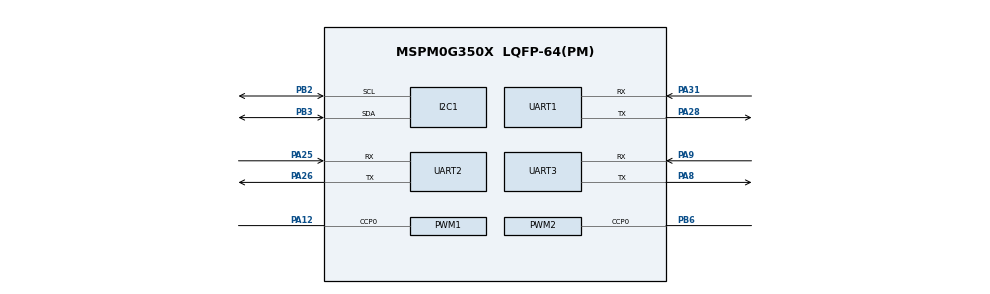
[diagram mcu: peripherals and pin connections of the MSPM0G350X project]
/**
 * @cliArgs --device "MSPM0G350X" --part "Default" --package "LQFP-64(PM)" --product "mspm0_sdk@2.10.00.04"
 * @versions {"tool":"1.26.2+4477"}
 */

/**
 * Import the modules used in this configuration.
 */
const GPIO    = scripting.addModule("/ti/driverlib/GPIO", {}, false);
const GPIO1   = GPIO.addInstance();
const GPIO2   = GPIO.addInstance();
const GPIO3   = GPIO.addInstance();
const GPIO4   = GPIO.addInstance();
const I2C     = scripting.addModule("/ti/driverlib/I2C", {}, false);
const I2C1    = I2C.addInstance();
const PWM     = scripting.addModule("/ti/driverlib/PWM", {}, false);
const PWM1    = PWM.addInstance();
const PWM2    = PWM.addInstance();
const SYSCTL  = scripting.addModule("/ti/driverlib/SYSCTL");
const SYSTICK = scripting.addModule("/ti/driverlib/SYSTICK");
const UART    = scripting.addModule("/ti/driverlib/UART", {}, false);
const UART1   = UART.addInstance();
const UART2   = UART.addInstance();
const UART3   = UART.addInstance();
const UART4   = UART.addInstance();

/**
 * Write custom configuration values to the imported modules.
 */
const divider6       = system.clockTree["PLL_CLK2X_DIV"];
divider6.divideValue = 4;

const divider7       = system.clockTree["PLL_PDIV"];
divider7.divideValue = 2;

const divider9       = system.clockTree["UDIV"];
divider9.divideValue = 2;

const multiplier2         = system.clockTree["PLL_QDIV"];
multiplier2.multiplyValue = 10;

const mux8       = system.clockTree["HSCLKMUX"];
mux8.inputSelect = "HSCLKMUX_SYSPLL2X";

GPIO1.$name                         = "MOTOR_DIR";
GPIO1.port                          = "PORTA";
GPIO1.associatedPins.create(4);
GPIO1.associatedPins[0].$name       = "MOTOR1_DIR";
GPIO1.associatedPins[0].assignedPin = "16";
GPIO1.associatedPins[1].$name       = "MOTOR2_DIR";
GPIO1.associatedPins[1].assignedPin = "17";
GPIO1.associatedPins[2].$name       = "MOTOR1_ENABLE";
GPIO1.associatedPins[2].assignedPin = "18";
GPIO1.associatedPins[3].$name       = "MOTOR2_ENABLE";
GPIO1.associatedPins[3].assignedPin = "15";

const Board = scripting.addModule("/ti/driverlib/Board", {}, false);

GPIO2.$name                          = "LINE_SENSOR";
GPIO2.port                           = "PORTB";
GPIO2.associatedPins.create(12);
GPIO2.associatedPins[0].$name        = "LINE0";
GPIO2.associatedPins[0].direction    = "INPUT";
GPIO2.associatedPins[0].assignedPin  = "0";
GPIO2.associatedPins[1].$name        = "LINE1";
GPIO2.associatedPins[1].direction    = "INPUT";
GPIO2.associatedPins[1].assignedPin  = "1";
GPIO2.associatedPins[2].$name        = "LINE2";
GPIO2.associatedPins[2].direction    = "INPUT";
GPIO2.associatedPins[2].assignedPin  = "4";
GPIO2.associatedPins[3].$name        = "LINE3";
GPIO2.associatedPins[3].direction    = "INPUT";
GPIO2.associatedPins[3].assignedPin  = "5";
GPIO2.associatedPins[4].$name        = "LINE4";
GPIO2.associatedPins[4].direction    = "INPUT";
GPIO2.associatedPins[4].assignedPin  = "7";
GPIO2.associatedPins[5].$name        = "LINE5";
GPIO2.associatedPins[5].direction    = "INPUT";
GPIO2.associatedPins[5].assignedPin  = "8";
GPIO2.associatedPins[6].$name        = "LINE6";
GPIO2.associatedPins[6].direction    = "INPUT";
GPIO2.associatedPins[6].assignedPin  = "9";
GPIO2.associatedPins[7].$name        = "LINE7";
GPIO2.associatedPins[7].direction    = "INPUT";
GPIO2.associatedPins[7].assignedPin  = "10";
GPIO2.associatedPins[8].$name        = "LINE8";
GPIO2.associatedPins[8].direction    = "INPUT";
GPIO2.associatedPins[8].assignedPin  = "11";
GPIO2.associatedPins[9].$name        = "LINE9";
GPIO2.associatedPins[9].direction    = "INPUT";
GPIO2.associatedPins[9].assignedPin  = "12";
GPIO2.associatedPins[10].$name       = "LINE10";
GPIO2.associatedPins[10].direction   = "INPUT";
GPIO2.associatedPins[10].assignedPin = "13";
GPIO2.associatedPins[11].$name       = "LINE11";
GPIO2.associatedPins[11].direction   = "INPUT";
GPIO2.associatedPins[11].assignedPin = "14";

GPIO3.$name                              = "BUTTONS";
GPIO3.port                               = "PORTA";
GPIO3.associatedPins.create(3);
GPIO3.associatedPins[0].$name            = "MODE";
GPIO3.associatedPins[0].direction        = "INPUT";
GPIO3.associatedPins[0].internalResistor = "PULL_UP";
GPIO3.associatedPins[0].assignedPin      = "14";
GPIO3.associatedPins[1].$name            = "UP";
GPIO3.associatedPins[1].direction        = "INPUT";
GPIO3.associatedPins[1].internalResistor = "PULL_UP";
GPIO3.associatedPins[1].assignedPin      = "24";
GPIO3.associatedPins[2].$name            = "DOWN";
GPIO3.associatedPins[2].direction        = "INPUT";
GPIO3.associatedPins[2].internalResistor = "PULL_UP";
GPIO3.associatedPins[2].assignedPin      = "29";

GPIO4.$name                              = "EXTRA_BUTTONS";
GPIO4.port                               = "PORTA";
GPIO4.associatedPins.create(5);
GPIO4.associatedPins[0].$name            = "KEY1";
GPIO4.associatedPins[0].direction        = "INPUT";
GPIO4.associatedPins[0].internalResistor = "PULL_UP";
GPIO4.associatedPins[0].assignedPin      = "30";
GPIO4.associatedPins[1].$name            = "KEY2";
GPIO4.associatedPins[1].direction        = "INPUT";
GPIO4.associatedPins[1].internalResistor = "PULL_UP";
GPIO4.associatedPins[1].assignedPin      = "7";
GPIO4.associatedPins[2].$name            = "KEY3";
GPIO4.associatedPins[2].direction        = "INPUT";
GPIO4.associatedPins[2].internalResistor = "PULL_UP";
GPIO4.associatedPins[2].assignedPin      = "10";
GPIO4.associatedPins[3].$name            = "KEY4";
GPIO4.associatedPins[3].direction        = "INPUT";
GPIO4.associatedPins[3].internalResistor = "PULL_UP";
GPIO4.associatedPins[3].assignedPin      = "11";
GPIO4.associatedPins[4].$name            = "KEY5";
GPIO4.associatedPins[4].direction        = "INPUT";
GPIO4.associatedPins[4].internalResistor = "PULL_UP";
GPIO4.associatedPins[4].assignedPin      = "13";

I2C1.$name                             = "OLED";
I2C1.basicEnableController             = true;
I2C1.advDigitalGlitchFilter            = "CLOCKS_1";
I2C1.basicControllerStandardBusSpeed   = "Fast";
I2C1.peripheral.$assign                = "I2C1";
I2C1.peripheral.sdaPin.$assign         = "PB3";
I2C1.peripheral.sclPin.$assign         = "PB2";
I2C1.sdaPinConfig.hideOutputInversion  = scripting.forceWrite(false);
I2C1.sdaPinConfig.onlyInternalResistor = scripting.forceWrite(false);
I2C1.sdaPinConfig.passedPeripheralType = scripting.forceWrite("Digital");
I2C1.sdaPinConfig.$name                = "OLED_SDA";
I2C1.sdaPinConfig.enableConfig         = true;
I2C1.sdaPinConfig.internalResistor     = "PULL_UP";
I2C1.sclPinConfig.hideOutputInversion  = scripting.forceWrite(false);
I2C1.sclPinConfig.onlyInternalResistor = scripting.forceWrite(false);
I2C1.sclPinConfig.passedPeripheralType = scripting.forceWrite("Digital");
I2C1.sclPinConfig.$name                = "OLED_SCL";
I2C1.sclPinConfig.enableConfig         = true;
I2C1.sclPinConfig.internalResistor     = "PULL_UP";

PWM1.$name                              = "PITCH_PWM";
PWM1.timerCount                         = 3500;
PWM1.clockDivider                       = 8;
PWM1.ccIndex                            = [0];
PWM1.PWM_CHANNEL_0.$name                = "MOTOR1_STEP";
PWM1.PWM_CHANNEL_0.dutyCycle            = 1;
PWM1.PWM_CHANNEL_0.ccValue              = 3475;
PWM1.ccp0PinConfig.direction            = scripting.forceWrite("OUTPUT");
PWM1.ccp0PinConfig.hideOutputInversion  = scripting.forceWrite(false);
PWM1.ccp0PinConfig.onlyInternalResistor = scripting.forceWrite(false);
PWM1.ccp0PinConfig.passedPeripheralType = scripting.forceWrite("Digital");
PWM1.ccp0PinConfig.$name                = "ti_driverlib_gpio_GPIOPinGeneric0";
PWM1.peripheral.$assign                 = "TIMG0";
PWM1.peripheral.ccp0Pin.$assign         = "PA12";

PWM2.$name                              = "YAW_PWM";
PWM2.timerCount                         = 3500;
PWM2.clockDivider                       = 8;
PWM2.clockPrescale                      = 2;
PWM2.ccIndex                            = [0];
PWM2.PWM_CHANNEL_0.$name                = "MOTOR2_STEP";
PWM2.PWM_CHANNEL_0.dutyCycle            = 1;
PWM2.PWM_CHANNEL_0.ccValue              = 3475;
PWM2.ccp0PinConfig.direction            = scripting.forceWrite("OUTPUT");
PWM2.ccp0PinConfig.hideOutputInversion  = scripting.forceWrite(false);
PWM2.ccp0PinConfig.onlyInternalResistor = scripting.forceWrite(false);
PWM2.ccp0PinConfig.passedPeripheralType = scripting.forceWrite("Digital");
PWM2.ccp0PinConfig.$name                = "ti_driverlib_gpio_GPIOPinGeneric2";
PWM2.peripheral.$assign                 = "TIMG6";
PWM2.peripheral.ccp0Pin.$assign         = "PB6";

SYSCTL.MCLKSource            = "HSCLK";
SYSCTL.SYSPLL_CLK2XEn        = true;
SYSCTL.SYSPLL_CLK2XDiv       = 1;
SYSCTL.HSCLKSource           = "SYSPLLCLK2X";
SYSCTL.validateClkStatus     = true;
SYSCTL.SYSPLL_Qdiv           = 5;
SYSCTL.forceDefaultClkConfig = true;
SYSCTL.clockTreeEn           = true;

SYSTICK.systickEnable = true;
SYSTICK.periodEnable  = true;
SYSTICK.period        = 80000;

UART1.$name                            = "TRACKING_UART";
UART1.enabledInterrupts                = ["FRAMING_ERROR","NOISE_ERROR","OVERRUN_ERROR","PARITY_ERROR","RX"];
UART1.targetBaudRate                   = 230400;
UART1.peripheral.$assign               = "UART0";
UART1.peripheral.rxPin.$assign         = "PA31";
UART1.peripheral.txPin.$assign         = "PA28";
UART1.txPinConfig.direction            = scripting.forceWrite("OUTPUT");
UART1.txPinConfig.hideOutputInversion  = scripting.forceWrite(false);
UART1.txPinConfig.onlyInternalResistor = scripting.forceWrite(false);
UART1.txPinConfig.passedPeripheralType = scripting.forceWrite("Digital");
UART1.txPinConfig.$name                = "ti_driverlib_gpio_GPIOPinGeneric4";
UART1.rxPinConfig.hideOutputInversion  = scripting.forceWrite(false);
UART1.rxPinConfig.onlyInternalResistor = scripting.forceWrite(false);
UART1.rxPinConfig.passedPeripheralType = scripting.forceWrite("Digital");
UART1.rxPinConfig.$name                = "ti_driverlib_gpio_GPIOPinGeneric5";

UART2.$name                            = "IMU601";
UART2.targetBaudRate                   = 115200;
UART2.enabledInterrupts                = ["FRAMING_ERROR","NOISE_ERROR","OVERRUN_ERROR","PARITY_ERROR","RX"];
UART2.peripheral.$assign               = "UART3";
UART2.peripheral.rxPin.$assign         = "PA25";
UART2.peripheral.txPin.$assign         = "PA26";
UART2.txPinConfig.$name                = "ti_driverlib_gpio_GPIOPinGeneric8";
UART2.txPinConfig.direction            = scripting.forceWrite("OUTPUT");
UART2.txPinConfig.hideOutputInversion  = scripting.forceWrite(false);
UART2.txPinConfig.onlyInternalResistor = scripting.forceWrite(false);
UART2.txPinConfig.passedPeripheralType = scripting.forceWrite("Digital");
UART2.rxPinConfig.$name                = "ti_driverlib_gpio_GPIOPinGeneric9";
UART2.rxPinConfig.hideOutputInversion  = scripting.forceWrite(false);
UART2.rxPinConfig.onlyInternalResistor = scripting.forceWrite(false);
UART2.rxPinConfig.passedPeripheralType = scripting.forceWrite("Digital");

UART3.$name                            = "CHASSIS_UART";
UART3.targetBaudRate                   = 115200;
UART3.enabledInterrupts                = ["FRAMING_ERROR","NOISE_ERROR","OVERRUN_ERROR","PARITY_ERROR","RX"];
UART3.peripheral.$assign               = "UART1";
UART3.peripheral.rxPin.$assign         = "PA9";
UART3.peripheral.txPin.$assign         = "PA8";
UART3.txPinConfig.$name                = "ti_driverlib_gpio_GPIOPinGeneric10";
UART3.txPinConfig.direction            = scripting.forceWrite("OUTPUT");
UART3.txPinConfig.hideOutputInversion  = scripting.forceWrite(false);
UART3.txPinConfig.onlyInternalResistor = scripting.forceWrite(false);
UART3.txPinConfig.passedPeripheralType = scripting.forceWrite("Digital");
UART3.rxPinConfig.$name                = "ti_driverlib_gpio_GPIOPinGeneric11";
UART3.rxPinConfig.hideOutputInversion  = scripting.forceWrite(false);
UART3.rxPinConfig.onlyInternalResistor = scripting.forceWrite(false);
UART3.rxPinConfig.passedPeripheralType = scripting.forceWrite("Digital");

UART4.$name             = "UART_0";
UART4.txPinConfig.$name = "ti_driverlib_gpio_GPIOPinGeneric1";
UART4.rxPinConfig.$name = "ti_driverlib_gpio_GPIOPinGeneric3";

/**
 * Pinmux solution for unlocked pins/peripherals. This ensures that minor changes to the automatic solver in a future
 * version of the tool will not impact the pinmux you originally saw.  These lines can be completely deleted in order to
 * re-solve from scratch.
 */
GPIO1.associatedPins[0].pin.$suggestSolution  = "PA16";
GPIO1.associatedPins[1].pin.$suggestSolution  = "PA17";
GPIO1.associatedPins[2].pin.$suggestSolution  = "PA18";
GPIO1.associatedPins[3].pin.$suggestSolution  = "PA15";
Board.peripheral.$suggestSolution             = "DEBUGSS";
Board.peripheral.swclkPin.$suggestSolution    = "PA20";
Board.peripheral.swdioPin.$suggestSolution    = "PA19";
GPIO2.associatedPins[0].pin.$suggestSolution  = "PB0";
GPIO2.associatedPins[1].pin.$suggestSolution  = "PB1";
GPIO2.associatedPins[2].pin.$suggestSolution  = "PB4";
GPIO2.associatedPins[3].pin.$suggestSolution  = "PB5";
GPIO2.associatedPins[4].pin.$suggestSolution  = "PB7";
GPIO2.associatedPins[5].pin.$suggestSolution  = "PB8";
GPIO2.associatedPins[6].pin.$suggestSolution  = "PB9";
GPIO2.associatedPins[7].pin.$suggestSolution  = "PB10";
GPIO2.associatedPins[8].pin.$suggestSolution  = "PB11";
GPIO2.associatedPins[9].pin.$suggestSolution  = "PB12";
GPIO2.associatedPins[10].pin.$suggestSolution = "PB13";
GPIO2.associatedPins[11].pin.$suggestSolution = "PB14";
GPIO3.associatedPins[0].pin.$suggestSolution  = "PA14";
GPIO3.associatedPins[1].pin.$suggestSolution  = "PA24";
GPIO3.associatedPins[2].pin.$suggestSolution  = "PA29";
GPIO4.associatedPins[0].pin.$suggestSolution  = "PA30";
GPIO4.associatedPins[1].pin.$suggestSolution  = "PA7";
GPIO4.associatedPins[2].pin.$suggestSolution  = "PA10";
GPIO4.associatedPins[3].pin.$suggestSolution  = "PA11";
GPIO4.associatedPins[4].pin.$suggestSolution  = "PA13";
UART4.peripheral.$suggestSolution             = "UART2";
UART4.peripheral.rxPin.$suggestSolution       = "PA22";
UART4.peripheral.txPin.$suggestSolution       = "PA21";
